# SPC1169 register map
File version: 2022071043481212
CPU: cm4 r1p0, little endian, no MPU, FPU, 4 interrupt priority bits
Registers are 32-bit, read-write, reset 0x0 unless marked. A register's access mark holds for its fields unless they carry their own. Offsets are from the block's base; [hi:lo] are bit positions; {n}, {i} and the like mark numbered series; 'fields as' and 'values as' point back to an identical list.

## COMP
Base 0x40003000
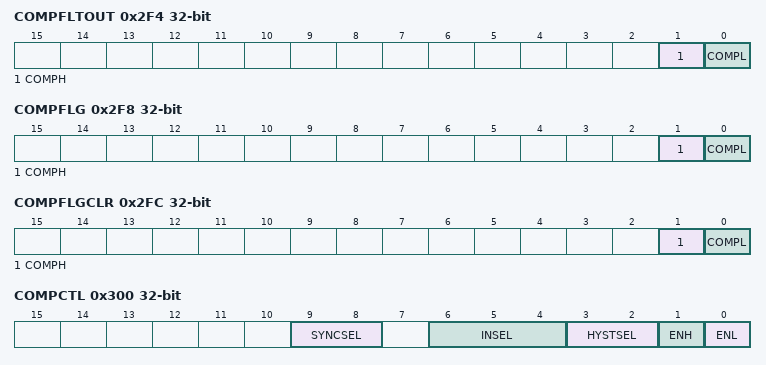
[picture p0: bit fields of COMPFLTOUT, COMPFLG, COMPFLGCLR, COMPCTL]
0x2F4 COMPFLTOUT ro — Comparator Filter Output Register
  [1] COMPH — COMPH filtered output without latch
    0=LOW (Input is lower than the high-boundary); 1=HIGH (Input is higher than the high-boundary)
  [0] COMPL — COMPL filtered output without latch
    0=LOW (Input is higher than the low-boundary); 1=HIGH (Input is lower than the low-boundary)
0x2F8 COMPFLG ro — Comparator Flag Register
  [1] COMPH — Latched COMPFLTOUT[COMPH]
    0=LOW (Input has been lower than the high-boundary); 1=HIGH (Input has been higher than the high-boundary)
  [0] COMPL — Latched COMPFLTOUT[COMPL]
    0=LOW (Input has been higher than the low-boundary); 1=HIGH (Input has been lower than the low-boundary)
0x2FC COMPFLGCLR — Comparator Flag Clear Register
  [1] COMPH — Latched COMPH flag clear
    0=NO_EFFECT (Write 0 has no effect and always reads back 0); 1=CLEAR (Write 1 clears COMPFLG[COMPH]. This bit is self-cleared.)
  [0] COMPL — Latched COMPL flag clear
    0=NO_EFFECT (Write 0 has no effect and always reads back 0); 1=CLEAR (Write 1 clears COMPFLG[COMPL]. This bit is self-cleared.)
0x300 COMPCTL — Comparator 0 Control Register
  [9:8] SYNCSEL — Select the synchronous output from PWM[SYNCSEL]
    {v}=PWM{v}SYNCO (PWM{v} synchronous output) (v=0..3)
  [6:4] INSEL — COMP0 input select
    0=DPGAN_OUT; 1=DPGAP_OUT; 2=SPGA_OUT; {v}=ANA_IN{v-3} (v=3..7)
  [3:2] HYSTSEL — COMP0 hysteresis select
    0=0_MV; 1=12_MV; 2=24_MV; 3=36_MV
  [1] ENH — COMP0H enable
    0=DISABLE (Disable COMPH); 1=ENABLE (Enable COMPH)
  [0] ENL — COMP0L enable
    0=DISABLE (Disable COMPL); 1=ENABLE (Enable COMPL)
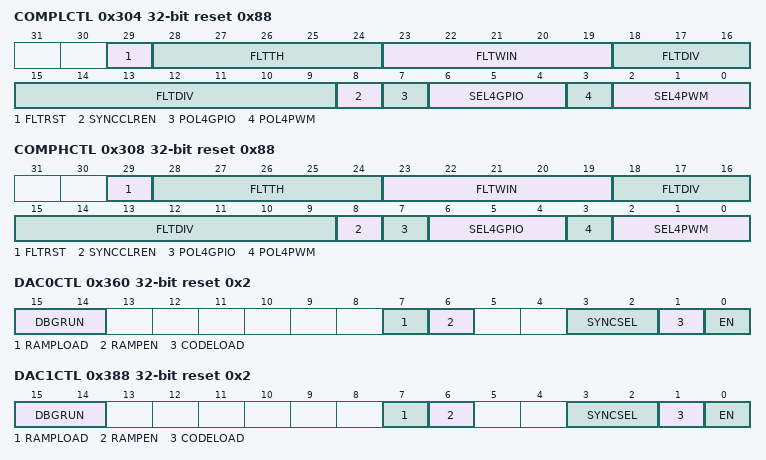
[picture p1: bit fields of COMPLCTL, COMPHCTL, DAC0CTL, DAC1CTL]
0x304 COMPLCTL reset 0x88 — COMP0L Control Register
  [29] FLTRST — Reset all registers in the filter with the input
    0=NO_EFFECT (Write 0 has no effect. Always read back 0.); 1=RESET (Write 1 will fill all registers in the filter with the input)
  [28:24] FLTTH — Filter's threshold is (FLTTH+1) 1's/0's for output to toggle
  [23:19] FLTWIN — Filter's window size is (FLTWIN+1) samples
  [18:9] FLTDIV — Filter's clock dividing ratio is (FLTDIV+1)
  [8] SYNCCLREN — Enable latched COMP0L status clear by PWMSYNC
    0=DISABLE (PWMSYNC does not affect the latched COMPL status); 1=ENABLE (PWMSYNC will clear the latched COMPL status)
  [7] POL4GPIO — COMP0L output polarity for GPIO
    0=ACTIVE_LOW (Output 0 when the comparator input is lower than the reference); 1=ACTIVE_HIGH (Output 1 when the comparator input is lower than the reference)
  [6:4] SEL4GPIO — COMP0L output select for GPIO
    0=ORIGINAL (Original output); 1=SYNC (Synchronous output with PWM clock); 2=FILTRED (Digital filter output); 3=LATCHED (Latched digital filter output); 4=ORIGINAL_OR_LATCHED (Original output or Latched digital filter output); 5=SYNC_OR_LATCHED (Synchronous output with PWM clock or Latched digital filter output); 6=FILTERED_OR_LATCHED (Digital filter output or the latched one); 7=ORIGINAL_OR_SYNC_OR_LATCHED (Original output or Synchronous output with PWM clock or Latched digital filter output)
  [3] POL4PWM — COMP0L output polarity for PWM
    values as POL4GPIO
  [2:0] SEL4PWM — COMP0L output select for PWM
    values as SEL4GPIO
0x308 COMPHCTL reset 0x88 — COMP0H Control Register
  [29] FLTRST — Reset all registers in the filter with the input
    values as COMPLCTL.FLTRST
  [28:24] FLTTH — Filter's threshold is (FLTTH+1) 1's/0's for output to toggle
  [23:19] FLTWIN — Filter's window size is (FLTWIN+1) samples
  [18:9] FLTDIV — Filter's clock dividing ratio is (FLTDIV+1)
  [8] SYNCCLREN — Enable latched COMP0H status clear by PWMSYNC
    0=DISABLE (PWMSYNC does not affect the latched COMPH status); 1=ENABLE (PWMSYNC will clear the latched COMPH status)
  [7] POL4GPIO — COMP0H output polarity for GPIO
    0=ACTIVE_LOW (Output 0 when the comparator input is higher than the reference); 1=ACTIVE_HIGH (Output 1 when the comparator input is higher than the reference)
  [6:4] SEL4GPIO — COMP0H output select for GPIO
    values as COMPLCTL.SEL4GPIO
  [3] POL4PWM — COMP0H output polarity for PWM
    values as POL4GPIO
  [2:0] SEL4PWM — COMP0H output select for PWM
    values as COMPLCTL.SEL4GPIO
0x360 DAC0CTL reset 0x2 — DAC0 Control Register
  [15:14] DBGRUN — Behavior on CPU halted or lockup
    0=STOP_IMMEDIATELY; 1=STOP_AT_PWMSYNC (Stop at PWM synchronous event); 2=KEEP_RUN (Free running)
  [7] RAMPLOAD — DAC Ramp load mode
    0=SHADOW_MODE (Register shadowing is applied for ramping counter load from RAMPMAX); 1=DIRECT_MODE (RAMP counter is directly loaded from the latest RAMPMAX)
  [6] RAMPEN — DAC Ramping enable
    0=DISABLE (Disable ramping); 1=ENABLE (Enable ramping. DAC0CODEA is equivalent to the 10 MSBs of RAMP0CNT)
  [3:2] SYNCSEL — PWMSYNC is selected from PWM[SYNCSEL]
    {v}=PWM{v}SYNCO (PWM{v} synchronous output) (v=0..3)
  [1] CODELOAD — DAC code load mode
    0=SHADOW_MODE (DAC code is updated upon PWMSYNC event); 1=DIRECT_MODE (DAC code is immediately updated by writing to DAC0CODE)
  [0] EN — DAC enable
    0=DISABLE; 1=ENABLE
0x364 DAC0CODE
  [9:0] VAL — DAC code. When DAC0CTL[CODELOAD]=0, write to this field only affects the shadow code. When DAC0CTL[CODELOAD]=1, write to this field affects both the shadow code and the active code.
{0x368+0x28*i} DAC{i}CODEA ro (i=0..2) — DAC{i} Active Code Register
  [9:0] VAL — Active DAC code
0x36C RAMP0DLY — RAMP0 Delay Shadow Register
  [15:0] VAL — Delay from PWMSYNC to start of ramping
0x370 RAMP0DLYA ro — RAMP0 Delay Active Register
  [15:0] VAL — Delay from PWMSYNC to start of ramping
0x374 RAMP0DEC — RAMP0 Decrement Shadow Register
  [15:0] VAL — Step size for decremental ramping
0x378 RAMP0DECA ro — RAMP0 Decrement Active Register
  [15:0] VAL — Step size for decremental ramping
0x37C RAMP0MAX — RAMP0 Reload Value Shadow Register
  [15:0] VAL — Reload value when reset ramping
0x380 RAMP0MAXA ro — RAMP0 Reload Value Active Register
  [15:0] VAL — Reload value when reset ramping
0x384 RAMP0CNT ro — RAMP0 Count Register
  [15:0] VAL — Count number of RAMP0
0x388 DAC1CTL reset 0x2 — DAC1 Control Register
  [15:14] DBGRUN — Behavior on CPU halted or lockup
    values as DAC0CTL.DBGRUN
  [7] RAMPLOAD — DAC Ramp load mode
    values as DAC0CTL.RAMPLOAD
  [6] RAMPEN — DAC Ramping enable
    0=DISABLE (Disable ramping); 1=ENABLE (Enable ramping. DAC1CODEA is equivalent to the 10 MSBs of RAMP1CNT)
  [3:2] SYNCSEL — PWMSYNC is selected from PWM.SYNCSEL
    {v}=PWM{v}SYNCO (PWM{v} synchronous output) (v=0..3)
  [1] CODELOAD — DAC code load mode
    0=SHADOW_MODE (DAC code is updated upon PWMSYNC event); 1=DIRECT_MODE (DAC code is immediately updated by writing to DAC1CODE)
  [0] EN — DAC enable
    0=DISABLE; 1=ENABLE
0x38C DAC1CODE
  [9:0] VAL — DAC code. When DAC1CTL.CODELOAD=0, write to this field only affects the shadow code. When DAC1CTL.CODELOAD=1, write to this field affects both the shadow code and the active code.
0x394 RAMP1DLY — RAMP1 Delay Shadow Register
  [15:0] VAL — Delay from PWMSYNC to start of ramping
0x398 RAMP1DLYA ro — RAMP1 Delay Active Register
  [15:0] VAL — Delay from PWMSYNC to start of ramping
0x39C RAMP1DEC — RAMP1 Decrement Shadow Register
  [15:0] VAL — Step size for decremental ramping
0x3A0 RAMP1DECA ro — RAMP1 Decrement Active Register
  [15:0] VAL — Step size for decremental ramping
0x3A4 RAMP1MAX — RAMP1 Reload Value Shadow Register
  [15:0] VAL — Reload value when reset ramping
0x3A8 RAMP1MAXA ro — RAMP1 Reload Value Active Register
  [15:0] VAL — Reload value when reset ramping
0x3AC RAMP1CNT ro — RAMP1 Count Register
  [15:0] VAL — Count number of RAMP1
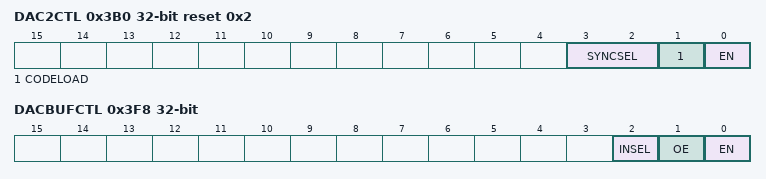
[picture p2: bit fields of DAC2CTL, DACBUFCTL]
0x3B0 DAC2CTL reset 0x2 — DAC2 Control Register
  [3:2] SYNCSEL — PWM synchronous output select
    {v}=PWM{v}SYNCO (PWM{v} synchronous output) (v=0..3)
  [1] CODELOAD — DAC code load mode
    0=SHADOW_MODE (DAC code is updated upon PWMSYNC event); 1=DIRECT_MODE (DAC code is immediately updated by writing to DAC2CODE)
  [0] EN — DAC enable
    0=DISABLE; 1=ENABLE
0x3B4 DAC2CODE
  [9:0] VAL — DAC code. When DAC2CTL.CODELOAD=0, write to this field only affects the shadow code. When DAC2CTL.CODELOAD=1, write to this field affects both the shadow code and the active code.
0x3F8 DACBUFCTL — DAC Buffer Control Register
  [2] INSEL — Select the DAC module
    0=DAC0; 1=DAC1
  [1] OE — Enable output to GPIO
    0=DISABLE; 1=ENABLE
  [0] EN — DAC buffer enable
    0=DISABLE; 1=ENABLE
0x3FC COMPREGKEY reset 0x1ACCE551 — COMP Register Write-Allow Key Register
  [31:0] KEY — Write 0x1ACCE551 to unlock protected COMP registers
